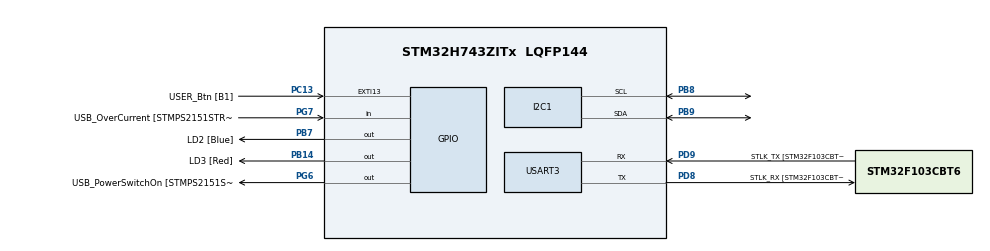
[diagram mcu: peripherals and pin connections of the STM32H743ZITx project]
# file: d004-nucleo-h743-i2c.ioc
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CORTEX_M7.CPU_DCache=Enabled
CORTEX_M7.CPU_ICache=Enabled
I2C1.Timing=0x307075B1
Mcu.Family=STM32H7
Mcu.Name=STM32H743ZITx
Mcu.Package=LQFP144
NVIC.I2C1_ER_IRQn=true\:2\:0\:true\:false\:true\:true\:true
NVIC.I2C1_EV_IRQn=true\:2\:0\:true\:false\:true\:true\:true
NVIC.PriorityGroup=NVIC_PRIORITYGROUP_4
PA1.GPIO_Label=RMII_REF_CLK
PA1.Signal=ETH_REF_CLK
PA10.GPIO_Label=USB_ID
PA10.Signal=USB_OTG_FS_ID
PA11.GPIO_Label=USB_DM
PA11.Signal=USB_OTG_FS_DM
PA12.GPIO_Label=USB_DP
PA12.Signal=USB_OTG_FS_DP
PA2.GPIO_Label=RMII_MDIO
PA2.Signal=ETH_MDIO
PA7.GPIO_Label=RMII_CRS_DV
PA7.Signal=ETH_CRS_DV
PA8.GPIO_Label=USB_SOF [TP1]
PA8.Signal=USB_OTG_FS_SOF
PA9.GPIO_Label=USB_VBUS
PA9.Signal=USB_OTG_FS_VBUS
PB13.GPIO_Label=RMII_TXD1
PB13.Signal=ETH_TXD1
PB14.GPIO_Label=LD3 [Red]
PB14.Signal=GPIO_Output
PB7.GPIO_Label=LD2 [Blue]
PB7.Signal=GPIO_Output
PB8.Mode=I2C
PB8.Signal=I2C1_SCL
PB9.Mode=I2C
PB9.Signal=I2C1_SDA
PC1.GPIO_Label=RMII_MDC
PC1.Signal=ETH_MDC
PC13.GPIO_Label=USER_Btn [B1]
PC13.Signal=GPXTI13
PC14-OSC32_IN\ (OSC32_IN).Signal=RCC_OSC32_IN
PC15-OSC32_OUT\ (OSC32_OUT).Signal=RCC_OSC32_OUT
PC4.GPIO_Label=RMII_RXD0
PC4.Signal=ETH_RXD0
PC5.GPIO_Label=RMII_RXD1
PC5.Signal=ETH_RXD1
PD8.GPIO_Label=STLK_RX [STM32F103CBT6_PA3]
PD8.Mode=Asynchronous
PD8.Signal=USART3_TX
PD9.GPIO_Label=STLK_TX [STM32F103CBT6_PA2]
PD9.Mode=Asynchronous
PD9.Signal=USART3_RX
PG11.GPIO_Label=RMII_TX_EN
PG11.Signal=ETH_TX_EN
PG13.GPIO_Label=RMII_TXD0
PG13.Signal=ETH_TXD0
PG6.GPIO_Label=USB_PowerSwitchOn [STMPS2151STR_EN]
PG6.Signal=GPIO_Output
PG7.GPIO_Label=USB_OverCurrent [STMPS2151STR_FAULT]
PG7.Signal=GPIO_Input
PH0-OSC_IN\ (PH0).GPIO_Label=MCO
PH0-OSC_IN\ (PH0).Mode=HSE-External-Oscillator
PH0-OSC_IN\ (PH0).Signal=RCC_OSC_IN
PH1-OSC_OUT\ (PH1).Mode=HSE-External-Oscillator
PH1-OSC_OUT\ (PH1).Signal=RCC_OSC_OUT
ProjectManager.HeapSize=0x200
ProjectManager.StackSize=0x400
ProjectManager.TargetToolchain=STM32CubeIDE
RCC.48MHZClocksFreq_Value=24000000
RCC.ADCFreq_Value=16125000
RCC.AHBFreq_Value=216000000
RCC.APB1CLKDivider=RCC_HCLK_DIV4
RCC.APB1Freq_Value=120000000
RCC.APB1TimFreq_Value=108000000
RCC.APB2CLKDivider=RCC_HCLK_DIV2
RCC.APB2Freq_Value=120000000
RCC.APB2TimFreq_Value=216000000
RCC.APB3Freq_Value=120000000
RCC.APB4Freq_Value=120000000
RCC.CortexFreq_Value=480000000
RCC.D1PPRE=RCC_APB3_DIV2
RCC.D2PPRE1=RCC_APB1_DIV2
RCC.D2PPRE2=RCC_APB2_DIV2
RCC.D3PPRE=RCC_APB4_DIV2
RCC.DIVM1=1
RCC.DIVN1=120
RCC.DIVQ1=4
RCC.HCLKFreq_Value=240000000
RCC.HPRE=RCC_HCLK_DIV2
RCC.HSE_VALUE=8000000
RCC.HSI_VALUE=64000000
RCC.PLLFRACN=0
RCC.PLLM=25
RCC.PLLMUL=RCC_PLL_MUL9
RCC.PLLN=432
RCC.PLLQ=9
RCC.PLLSourceVirtual=RCC_PLLSOURCE_HSE
RCC.PRESCALERUSB=RCC_USBCLKSOURCE_PLL_DIV1_5
RCC.SYSCLKFreq_VALUE=480000000
RCC.SYSCLKSource=RCC_SYSCLKSOURCE_PLLCLK
RCC.SYSCLKSourceVirtual=RCC_SYSCLKSOURCE_PLLCLK
RCC.USBFreq_Value=240000000
RCC.VCOOutputFreq_Value=432000000
USART3.VirtualMode-Asynchronous=VM_ASYNC
board=NUCLEO-H743ZI

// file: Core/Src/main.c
/* USER CODE BEGIN Header */
/**
 ******************************************************************************
 * @file           : main.c
 * @brief          : Main program body
 ******************************************************************************
 * @attention
 *
 * <h2><center>&copy; Copyright (c) 2019 STMicroelectronics.
 * All rights reserved.</center></h2>
 *
 * This software component is licensed by ST under BSD 3-Clause license,
 * the "License"; You may not use this file except in compliance with the
 * License. You may obtain a copy of the License at:
 *                        opensource.org/licenses/BSD-3-Clause
 *
 ******************************************************************************
 */
/* USER CODE END Header */

#include "main.h"

I2C_HandleTypeDef hi2c1;

UART_HandleTypeDef huart3;

void SystemClock_Config(void);
static void MX_GPIO_Init(void);
static void MX_USART3_UART_Init(void);
static void MX_I2C1_Init(void);

/* USER CODE BEGIN 0 */
uint8_t buf[1];

/*
 * Output a message when I2C interrupt is triggered.
 */

void HAL_I2C_MasterTxCpltCallback(I2C_HandleTypeDef *hi2c)
{
    // Check if the interrupt is triggered from our I2C
    if (hi2c == &hi2c1)
        while (1)
        {   // Comming here with NAK receive is buggy
            HAL_GPIO_TogglePin(LD2_GPIO_Port, LD2_Pin);    // Toggle Gree LED.
            HAL_Delay(250);
        }
}

void HAL_I2C_ErrorCallback(I2C_HandleTypeDef *hi2c)
{
    // Check if the interrupt is triggered from our I2C
    if (hi2c == &hi2c1)
        HAL_GPIO_WritePin(LD3_GPIO_Port, LD3_Pin, GPIO_PIN_SET);    // turn on RED LED.
}
/* USER CODE END 0 */

int main(void)
{

  /* Enable I-Cache---------------------------------------------------------*/
  SCB_EnableICache();

  /* Enable D-Cache---------------------------------------------------------*/
  SCB_EnableDCache();

  /* MCU Configuration--------------------------------------------------------*/

  /* Reset of all peripherals, Initializes the Flash interface and the Systick. */
  HAL_Init();

  /* Configure the system clock */
  SystemClock_Config();

  /* Initialize all configured peripherals */
  MX_GPIO_Init();
  MX_USART3_UART_Init();
  MX_I2C1_Init();
  /* USER CODE BEGIN 2 */

    /*
     * Starting I2C Master Transmission. This transmission issues only address phase.
     * The I2C device address is 0, and assumes there is no device.
     *
     * If the I2C bus is correctly pulled up, the address phase to the "vacant" address
     * is interpreted as NAK response immediately. This is specification of the I2C bus.
     */

    HAL_I2C_Master_Transmit_IT(
                               &hi2c1,
                               0x02,
                               buf,
                               0);

  /* USER CODE END 2 */

  /* Infinite loop */
    while (1)
    {

    }
}

void SystemClock_Config(void)
{
  RCC_OscInitTypeDef RCC_OscInitStruct = {0};
  RCC_ClkInitTypeDef RCC_ClkInitStruct = {0};
  RCC_PeriphCLKInitTypeDef PeriphClkInitStruct = {0};

  /** Supply configuration update enable
  */
  HAL_PWREx_ConfigSupply(PWR_LDO_SUPPLY);
  /** Configure the main internal regulator output voltage
  */
  __HAL_PWR_VOLTAGESCALING_CONFIG(PWR_REGULATOR_VOLTAGE_SCALE0);

  while(!__HAL_PWR_GET_FLAG(PWR_FLAG_VOSRDY)) {}
  /** Initializes the CPU, AHB and APB busses clocks
  */
  RCC_OscInitStruct.OscillatorType = RCC_OSCILLATORTYPE_HSE;
  RCC_OscInitStruct.HSEState = RCC_HSE_ON;
  RCC_OscInitStruct.PLL.PLLState = RCC_PLL_ON;
  RCC_OscInitStruct.PLL.PLLSource = RCC_PLLSOURCE_HSE;
  RCC_OscInitStruct.PLL.PLLM = 1;
  RCC_OscInitStruct.PLL.PLLN = 120;
  RCC_OscInitStruct.PLL.PLLP = 2;
  RCC_OscInitStruct.PLL.PLLQ = 4;
  RCC_OscInitStruct.PLL.PLLR = 2;
  RCC_OscInitStruct.PLL.PLLRGE = RCC_PLL1VCIRANGE_3;
  RCC_OscInitStruct.PLL.PLLVCOSEL = RCC_PLL1VCOWIDE;
  RCC_OscInitStruct.PLL.PLLFRACN = 0;
  if (HAL_RCC_OscConfig(&RCC_OscInitStruct) != HAL_OK)
  {
    Error_Handler();
  }
  /** Initializes the CPU, AHB and APB busses clocks
  */
  RCC_ClkInitStruct.ClockType = RCC_CLOCKTYPE_HCLK|RCC_CLOCKTYPE_SYSCLK
                              |RCC_CLOCKTYPE_PCLK1|RCC_CLOCKTYPE_PCLK2
                              |RCC_CLOCKTYPE_D3PCLK1|RCC_CLOCKTYPE_D1PCLK1;
  RCC_ClkInitStruct.SYSCLKSource = RCC_SYSCLKSOURCE_PLLCLK;
  RCC_ClkInitStruct.SYSCLKDivider = RCC_SYSCLK_DIV1;
  RCC_ClkInitStruct.AHBCLKDivider = RCC_HCLK_DIV2;
  RCC_ClkInitStruct.APB3CLKDivider = RCC_APB3_DIV2;
  RCC_ClkInitStruct.APB1CLKDivider = RCC_APB1_DIV2;
  RCC_ClkInitStruct.APB2CLKDivider = RCC_APB2_DIV2;
  RCC_ClkInitStruct.APB4CLKDivider = RCC_APB4_DIV2;

  if (HAL_RCC_ClockConfig(&RCC_ClkInitStruct, FLASH_LATENCY_4) != HAL_OK)
  {
    Error_Handler();
  }
  PeriphClkInitStruct.PeriphClockSelection = RCC_PERIPHCLK_USART3|RCC_PERIPHCLK_I2C1;
  PeriphClkInitStruct.Usart234578ClockSelection = RCC_USART234578CLKSOURCE_D2PCLK1;
  PeriphClkInitStruct.I2c123ClockSelection = RCC_I2C123CLKSOURCE_D2PCLK1;
  if (HAL_RCCEx_PeriphCLKConfig(&PeriphClkInitStruct) != HAL_OK)
  {
    Error_Handler();
  }
}

static void MX_I2C1_Init(void)
{

  hi2c1.Instance = I2C1;
  hi2c1.Init.Timing = 0x307075B1;
  hi2c1.Init.OwnAddress1 = 0;
  hi2c1.Init.AddressingMode = I2C_ADDRESSINGMODE_7BIT;
  hi2c1.Init.DualAddressMode = I2C_DUALADDRESS_DISABLE;
  hi2c1.Init.OwnAddress2 = 0;
  hi2c1.Init.OwnAddress2Masks = I2C_OA2_NOMASK;
  hi2c1.Init.GeneralCallMode = I2C_GENERALCALL_DISABLE;
  hi2c1.Init.NoStretchMode = I2C_NOSTRETCH_DISABLE;
  if (HAL_I2C_Init(&hi2c1) != HAL_OK)
  {
    Error_Handler();
  }
  /** Configure Analogue filter
  */
  if (HAL_I2CEx_ConfigAnalogFilter(&hi2c1, I2C_ANALOGFILTER_ENABLE) != HAL_OK)
  {
    Error_Handler();
  }
  /** Configure Digital filter
  */
  if (HAL_I2CEx_ConfigDigitalFilter(&hi2c1, 0) != HAL_OK)
  {
    Error_Handler();
  }

}

static void MX_USART3_UART_Init(void)
{

  huart3.Instance = USART3;
  huart3.Init.BaudRate = 115200;
  huart3.Init.WordLength = UART_WORDLENGTH_8B;
  huart3.Init.StopBits = UART_STOPBITS_1;
  huart3.Init.Parity = UART_PARITY_NONE;
  huart3.Init.Mode = UART_MODE_TX_RX;
  huart3.Init.HwFlowCtl = UART_HWCONTROL_NONE;
  huart3.Init.OverSampling = UART_OVERSAMPLING_16;
  huart3.Init.OneBitSampling = UART_ONE_BIT_SAMPLE_DISABLE;
  huart3.Init.ClockPrescaler = UART_PRESCALER_DIV1;
  huart3.AdvancedInit.AdvFeatureInit = UART_ADVFEATURE_NO_INIT;
  if (HAL_UART_Init(&huart3) != HAL_OK)
  {
    Error_Handler();
  }
  if (HAL_UARTEx_SetTxFifoThreshold(&huart3, UART_TXFIFO_THRESHOLD_1_8) != HAL_OK)
  {
    Error_Handler();
  }
  if (HAL_UARTEx_SetRxFifoThreshold(&huart3, UART_RXFIFO_THRESHOLD_1_8) != HAL_OK)
  {
    Error_Handler();
  }
  if (HAL_UARTEx_DisableFifoMode(&huart3) != HAL_OK)
  {
    Error_Handler();
  }

}

static void MX_GPIO_Init(void)
{
  GPIO_InitTypeDef GPIO_InitStruct = {0};

  /* GPIO Ports Clock Enable */
  __HAL_RCC_GPIOC_CLK_ENABLE();
  __HAL_RCC_GPIOH_CLK_ENABLE();
  __HAL_RCC_GPIOA_CLK_ENABLE();
  __HAL_RCC_GPIOB_CLK_ENABLE();
  __HAL_RCC_GPIOD_CLK_ENABLE();
  __HAL_RCC_GPIOG_CLK_ENABLE();

  /*Configure GPIO pin Output Level */
  HAL_GPIO_WritePin(GPIOB, LD3_Pin|LD2_Pin, GPIO_PIN_RESET);

  /*Configure GPIO pin Output Level */
  HAL_GPIO_WritePin(USB_PowerSwitchOn_GPIO_Port, USB_PowerSwitchOn_Pin, GPIO_PIN_RESET);

  /*Configure GPIO pin : USER_Btn_Pin */
  GPIO_InitStruct.Pin = USER_Btn_Pin;
  GPIO_InitStruct.Mode = GPIO_MODE_IT_RISING;
  GPIO_InitStruct.Pull = GPIO_NOPULL;
  HAL_GPIO_Init(USER_Btn_GPIO_Port, &GPIO_InitStruct);

  /*Configure GPIO pins : RMII_MDC_Pin RMII_RXD0_Pin RMII_RXD1_Pin */
  GPIO_InitStruct.Pin = RMII_MDC_Pin|RMII_RXD0_Pin|RMII_RXD1_Pin;
  GPIO_InitStruct.Mode = GPIO_MODE_AF_PP;
  GPIO_InitStruct.Pull = GPIO_NOPULL;
  GPIO_InitStruct.Speed = GPIO_SPEED_FREQ_LOW;
  GPIO_InitStruct.Alternate = GPIO_AF11_ETH;
  HAL_GPIO_Init(GPIOC, &GPIO_InitStruct);

  /*Configure GPIO pins : RMII_REF_CLK_Pin RMII_MDIO_Pin RMII_CRS_DV_Pin */
  GPIO_InitStruct.Pin = RMII_REF_CLK_Pin|RMII_MDIO_Pin|RMII_CRS_DV_Pin;
  GPIO_InitStruct.Mode = GPIO_MODE_AF_PP;
  GPIO_InitStruct.Pull = GPIO_NOPULL;
  GPIO_InitStruct.Speed = GPIO_SPEED_FREQ_LOW;
  GPIO_InitStruct.Alternate = GPIO_AF11_ETH;
  HAL_GPIO_Init(GPIOA, &GPIO_InitStruct);

  /*Configure GPIO pin : RMII_TXD1_Pin */
  GPIO_InitStruct.Pin = RMII_TXD1_Pin;
  GPIO_InitStruct.Mode = GPIO_MODE_AF_PP;
  GPIO_InitStruct.Pull = GPIO_NOPULL;
  GPIO_InitStruct.Speed = GPIO_SPEED_FREQ_LOW;
  GPIO_InitStruct.Alternate = GPIO_AF11_ETH;
  HAL_GPIO_Init(RMII_TXD1_GPIO_Port, &GPIO_InitStruct);

  /*Configure GPIO pins : LD3_Pin LD2_Pin */
  GPIO_InitStruct.Pin = LD3_Pin|LD2_Pin;
  GPIO_InitStruct.Mode = GPIO_MODE_OUTPUT_PP;
  GPIO_InitStruct.Pull = GPIO_NOPULL;
  GPIO_InitStruct.Speed = GPIO_SPEED_FREQ_LOW;
  HAL_GPIO_Init(GPIOB, &GPIO_InitStruct);

  /*Configure GPIO pin : USB_PowerSwitchOn_Pin */
  GPIO_InitStruct.Pin = USB_PowerSwitchOn_Pin;
  GPIO_InitStruct.Mode = GPIO_MODE_OUTPUT_PP;
  GPIO_InitStruct.Pull = GPIO_NOPULL;
  GPIO_InitStruct.Speed = GPIO_SPEED_FREQ_LOW;
  HAL_GPIO_Init(USB_PowerSwitchOn_GPIO_Port, &GPIO_InitStruct);

  /*Configure GPIO pin : USB_OverCurrent_Pin */
  GPIO_InitStruct.Pin = USB_OverCurrent_Pin;
  GPIO_InitStruct.Mode = GPIO_MODE_INPUT;
  GPIO_InitStruct.Pull = GPIO_NOPULL;
  HAL_GPIO_Init(USB_OverCurrent_GPIO_Port, &GPIO_InitStruct);

  /*Configure GPIO pins : USB_SOF_Pin USB_ID_Pin USB_DM_Pin USB_DP_Pin */
  GPIO_InitStruct.Pin = USB_SOF_Pin|USB_ID_Pin|USB_DM_Pin|USB_DP_Pin;
  GPIO_InitStruct.Mode = GPIO_MODE_AF_PP;
  GPIO_InitStruct.Pull = GPIO_NOPULL;
  GPIO_InitStruct.Speed = GPIO_SPEED_FREQ_LOW;
  GPIO_InitStruct.Alternate = GPIO_AF10_OTG1_FS;
  HAL_GPIO_Init(GPIOA, &GPIO_InitStruct);

  /*Configure GPIO pins : RMII_TX_EN_Pin RMII_TXD0_Pin */
  GPIO_InitStruct.Pin = RMII_TX_EN_Pin|RMII_TXD0_Pin;
  GPIO_InitStruct.Mode = GPIO_MODE_AF_PP;
  GPIO_InitStruct.Pull = GPIO_NOPULL;
  GPIO_InitStruct.Speed = GPIO_SPEED_FREQ_LOW;
  GPIO_InitStruct.Alternate = GPIO_AF11_ETH;
  HAL_GPIO_Init(GPIOG, &GPIO_InitStruct);

}

void Error_Handler(void)
{
}

/************************ (C) COPYRIGHT STMicroelectronics *****END OF FILE****/
